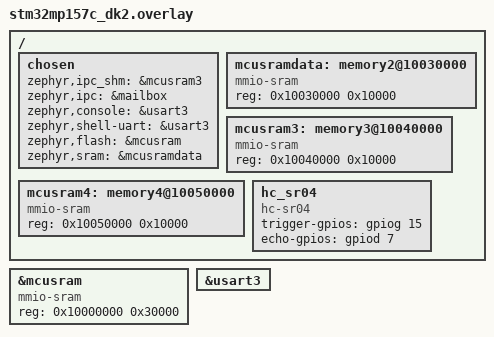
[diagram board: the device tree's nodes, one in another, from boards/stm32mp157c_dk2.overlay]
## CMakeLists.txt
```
cmake_minimum_required(VERSION 3.20.0)

find_package(Zephyr REQUIRED HINTS $ENV{ZEPHYR_BASE})
project(myapp)

# METAL_MAX_DEVICE_REGIONS is used to give the number of memory regions shared
# between processors. By default only one region is defined for the vrings
# and rpmsg buffers. The METAL_MAX_DEVICE_REGIONS has to be redifined to add a
# second region for the resource table.
zephyr_compile_definitions(METAL_MAX_DEVICE_REGIONS=2)

target_include_directories(app PRIVATE ${LIBMETAL_INCLUDE_DIR} ${OPENAMP_INCLUDE_DIR} ${PLATFORM_DIR})

target_sources(app PRIVATE src/main.cpp src/ipc.cpp src/ultrasonic.cpp)
```

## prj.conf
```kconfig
CONFIG_IPM=y
CONFIG_HEAP_MEM_POOL_SIZE=2048
CONFIG_OPENAMP=y
CONFIG_OPENAMP_RSC_TABLE_NUM_RPMSG_BUFF=8
CONFIG_OPENAMP_RSC_TABLE=y
CONFIG_OPENAMP_MASTER=n
CONFIG_SENSOR=y
CONFIG_UART_CONSOLE=y
CONFIG_LOG=y
CONFIG_CPP=y
CONFIG_REQUIRES_FULL_LIBCPP=y
CONFIG_CBPRINTF_FP_SUPPORT=y
CONFIG_ROMSTART_RELOCATION_ROM=y
```

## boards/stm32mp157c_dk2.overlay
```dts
/*
 * Copyright (c) 2020, STMICROLECTRONICS
 *
 * SPDX-License-Identifier: Apache-2.0
 */

/ {
	chosen {
		/*
		 * shared memory reserved for the inter-processor communication
		 */
		zephyr,ipc_shm = &mcusram3;
		zephyr,ipc = &mailbox;
		zephyr,console = &usart3;
		zephyr,shell-uart = &usart3;
		zephyr,flash = &mcusram;
		zephyr,sram = &mcusramdata;
	};

	mcusramdata: memory2@10030000 {
		device_type = "memory";
		compatible = "mmio-sram";
		reg = <0x10030000 0x10000>;
	};

	mcusram3: memory3@10040000 {
		device_type = "memory";
		compatible = "mmio-sram";
		reg = <0x10040000 0x10000>;
	};

	mcusram4: memory4@10050000 {
		device_type = "memory";
		compatible = "mmio-sram";
		reg = <0x10050000 0x10000>;
	};

	hc_sr04: hc_sr04 {
		compatible = "hc-sr04";
		trigger-gpios = <&gpiog 15 GPIO_ACTIVE_HIGH>;
		echo-gpios = <&gpiod 7 GPIO_ACTIVE_HIGH>;
	};
};

&mcusram {
	device_type = "memory";
	compatible = "mmio-sram";
	reg = <0x10000000 0x30000>;
};

&usart3 {
	status = "okay";
};
```

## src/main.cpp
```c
#include <stdio.h>
#include <zephyr/kernel.h>
#include "ipc.hpp"
#include "ultrasonic.hpp"

#define APP_TTY_TASK_STACK_SIZE (1536)
#define APP_ULTRASONIC_TASK_STACK_SIZE (500)
static struct k_thread thread_tty_data;
static struct k_thread thread_ultrasonic_data;
K_THREAD_STACK_DEFINE(thread_tty_stack, APP_TTY_TASK_STACK_SIZE);
K_THREAD_STACK_DEFINE(thread_ultrasonic_stack, APP_TTY_TASK_STACK_SIZE);

int main(void)
{
	k_thread_create(&thread_ultrasonic_data, thread_ultrasonic_stack, APP_ULTRASONIC_TASK_STACK_SIZE, ultrasonic_task, NULL, NULL, NULL, K_PRIO_COOP(7), 0, K_NO_WAIT);
	k_thread_create(&thread_tty_data, thread_tty_stack, APP_TTY_TASK_STACK_SIZE, ipc_task, NULL, NULL, NULL, K_PRIO_COOP(7), 0, K_NO_WAIT);

	while (1)
	{
		// printf("Distance: %.01f cm\n", get_distance());
		k_sleep(K_MSEC(100));
	}
	
	return 0;
}
```

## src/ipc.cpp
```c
#include "ipc.hpp"

#include <zephyr/device.h>
#include <string.h>
#include <stdlib.h>

#include <zephyr/drivers/ipm.h>

#include <openamp/open_amp.h>
#include <metal/device.h>
#include <resource_table.h>

#include "ultrasonic.hpp"

#define RPMSG_CHAN_NAME "rpmsg-tty"
#define SHM_DEVICE_NAME "shm"
// #define CONFIG_OPENAMP_IPC_DEV_NAME "$(dt_chosen_label,$(DT_CHOSEN_Z_IPC))"

#if !DT_HAS_CHOSEN(zephyr_ipc_shm)
#error "Application requires definition of shared memory for rpmsg"
#endif

/* Constants derived from device tree */
#define SHM_NODE        DT_CHOSEN(zephyr_ipc_shm)
#define SHM_START_ADDR  DT_REG_ADDR(SHM_NODE)
#define SHM_SIZE        DT_REG_SIZE(SHM_NODE)

static const struct device *ipm_handle;

static metal_phys_addr_t shm_physmap = SHM_START_ADDR;

struct metal_device shm_device = {
    .name = SHM_DEVICE_NAME,
    .num_regions = 2,
    .regions = {
        {.virt = NULL}, /* shared memory */
        {.virt = NULL}, /* rsc_table memory */
    },
    .node = { NULL },
    .irq_num = 0,
    .irq_info = NULL
};

static struct metal_io_region *shm_io;
static struct rpmsg_virtio_shm_pool shpool;

static struct metal_io_region *rsc_io;
static struct rpmsg_virtio_device rvdev;

static fw_resource_table *rsc_table;

static char rcv_msg[20];
static char tx_buffer[64];
static unsigned int rcv_len;
static struct rpmsg_endpoint rcv_ept;

static K_SEM_DEFINE(data_sem, 0, 1);
static K_SEM_DEFINE(data_rx_sem, 0, 1);

static void platform_ipm_callback(const struct device *device, void *context, uint32_t id, volatile void *data)
{
    k_sem_give(&data_sem);
}

static int rpmsg_recv_callback(struct rpmsg_endpoint *ept, void *data, size_t len, uint32_t src, void *priv)
{
    memcpy(rcv_msg, data, len);
    rcv_len = len;
    k_sem_give(&data_rx_sem);

    return RPMSG_SUCCESS;
}

static void receive_message(char **msg, unsigned int *len)
{
    while (k_sem_take(&data_rx_sem, K_NO_WAIT) != 0) {
        int status = k_sem_take(&data_sem, K_FOREVER);

        if (status == 0)
            rproc_virtio_notified(rvdev.vdev, VRING1_ID);
    }
    *len = rcv_len;
    *msg = rcv_msg;
}

static void new_service_cb(struct rpmsg_device *rdev, const char *name,
                           uint32_t src)
{
    printk("%s: unexpected ns service receive for name %s\n", __func__, name);
}

int mailbox_notify(void *priv, uint32_t id)
{
    ARG_UNUSED(priv);

    ipm_send(ipm_handle, 0, id, NULL, 0);

    return 0;
}

int platform_init(void)
{
    static struct fw_resource_table *rsc_tab_addr;
    int rsc_size;
    struct metal_device *device;
    struct metal_init_params metal_params = METAL_INIT_DEFAULTS;
    int status;

    status = metal_init(&metal_params);
    if (status) {
        printk("metal_init: failed: %d\n", status);
        return -1;
    }

    status = metal_register_generic_device(&shm_device);
    if (status) {
        printk("Couldn't register shared memory: %d\n", status);
        return -1;
    }

    status = metal_device_open("generic", SHM_DEVICE_NAME, &device);
    if (status) {
        printk("metal_device_open failed: %d\n", status);
        return -1;
    }

    /* declare shared memory region */
    metal_io_init(&device->regions[0], (void *)SHM_START_ADDR, &shm_physmap,
                  SHM_SIZE, -1, 0, NULL);

    shm_io = metal_device_io_region(device, 0);
    if (!shm_io) {
        printk("Failed to get shm_io region\n");
        return -1;
    }

    /* declare resource table region */
    rsc_table_get((void**)(&rsc_tab_addr), &rsc_size);
    rsc_table = (fw_resource_table*)rsc_tab_addr;

    metal_io_init(&device->regions[1], rsc_table,
                  (metal_phys_addr_t *)rsc_table, rsc_size, -1, 0, NULL);

    rsc_io = metal_device_io_region(device, 1);
    if (!rsc_io) {
        printk("Failed to get rsc_io region\n");
        return -1;
    }

    /* setup IPM */
    ipm_handle = device_get_binding(CONFIG_OPENAMP_IPC_DEV_NAME);
    if (!ipm_handle) {
        printk("Failed to find ipm device\n");
        return -1;
    }

    ipm_register_callback(ipm_handle, platform_ipm_callback, NULL);

    status = ipm_set_enabled(ipm_handle, 1);
    if (status) {
        printk("ipm_set_enabled failed\n");
        return -1;
    }

    return 0;
}

struct  rpmsg_device *
platform_create_rpmsg_vdev(unsigned int vdev_index,
                           unsigned int role,
                           void (*rst_cb)(struct virtio_device *vdev),
                           rpmsg_ns_bind_cb ns_cb)
{
    struct fw_rsc_vdev_vring *vring_rsc;
    struct virtio_device *vdev;
    int ret;

    vdev = rproc_virtio_create_vdev(VIRTIO_DEV_DEVICE, VDEV_ID,
                                    rsc_table_to_vdev(rsc_table),
                                    rsc_io, NULL, mailbox_notify, NULL);
    if (!vdev) {
        printk("failed to create vdev\r\n");
        return NULL;
    }

    /* wait master rpmsg init completion */
    rproc_virtio_wait_remote_ready(vdev);

    vring_rsc = rsc_table_get_vring0(rsc_table);
    ret = rproc_virtio_init_vring(vdev, 0, vring_rsc->notifyid,
                                  (void *)vring_rsc->da, rsc_io,
                                  vring_rsc->num, vring_rsc->align);
    if (ret) {
        printk("failed to init vring 0\r\n");
        goto failed;
    }

    vring_rsc = rsc_table_get_vring1(rsc_table);
    ret = rproc_virtio_init_vring(vdev, 1, vring_rsc->notifyid,
                                  (void *)vring_rsc->da, rsc_io,
                                  vring_rsc->num, vring_rsc->align);
    if (ret) {
        printk("failed to init vring 1\r\n");
        goto failed;
    }

    rpmsg_virtio_init_shm_pool(&shpool, NULL, SHM_SIZE);
    ret =  rpmsg_init_vdev(&rvdev, vdev, ns_cb, shm_io, &shpool);

    if (ret) {
        printk("failed rpmsg_init_vdev\r\n");
        goto failed;
    }

    return rpmsg_virtio_get_rpmsg_device(&rvdev);

failed:
    rproc_virtio_remove_vdev(vdev);

    return NULL;
}


void ipc_task(void *arg1, void *arg2, void *arg3)
{
    ARG_UNUSED(arg1);
    ARG_UNUSED(arg2);
    ARG_UNUSED(arg3);

    struct rpmsg_device *rpdev;
    char *msg;
    unsigned int len;
    int ret = 0;

    /* Initialize platform */
    ret = platform_init();
    if (ret) {
        printk("Failed to initialize platform\n");
        return;
    }

    rpdev = platform_create_rpmsg_vdev(0, VIRTIO_DEV_DEVICE, NULL,
                                       new_service_cb);
    if (!rpdev) {
        printk("Failed to create rpmsg virtio device\n");
        return;
    }

    ret = rpmsg_create_ept(&rcv_ept, rpdev, RPMSG_CHAN_NAME,
                           RPMSG_ADDR_ANY, RPMSG_ADDR_ANY,
                           rpmsg_recv_callback, NULL);
    if (ret != 0)
        printk("error while creating endpoint(%d)\n", ret);

    /* Handle incoming messsages and send replies when needed */
    for (;;) {
        receive_message(&msg, &len);
        
        int ret = 0;

        if (strcmp(msg, "dist\n") == 0)
        {
            float distance = get_distance();
            ret = snprintf(tx_buffer, sizeof(tx_buffer), "%f", (double)distance);
        }
        else
        {
            ret = snprintf(tx_buffer, sizeof(tx_buffer), "Not known command");
        }

        if (ret > 0)
        {
            rpmsg_send(&rcv_ept, tx_buffer, ret);
        }
        // printk("MESSAGE: %s\n", msg);
    }
}
```

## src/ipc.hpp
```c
#pragma once

void ipc_task(void *, void *, void *);
```

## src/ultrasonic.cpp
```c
#include "ultrasonic.hpp"
#include <zephyr/logging/log.h>
#include <zephyr/drivers/sensor.h>
LOG_MODULE_REGISTER(ultrasonic);

static const struct device *ultrasonic = DEVICE_DT_GET_ONE(hc_sr04);
constexpr int messure_count = 10;
static float distance[messure_count];
static struct k_mutex mutex;

static int trigger_measurement(float &range)
{
	int ret;
	static struct sensor_value distance = {-1, 0};
	
	ret = sensor_sample_fetch(ultrasonic);

	if (0 == ret)
	{
		ret = sensor_channel_get(ultrasonic, SENSOR_CHAN_DISTANCE, &distance);
		
		if (0 == ret)
		{
			k_mutex_lock(&mutex, K_FOREVER);
			range = sensor_value_to_float(&distance);
			k_mutex_unlock(&mutex);
		}
		else
		{
			LOG_ERR("%s - Cannot take measurement: %d", ultrasonic->name, ret);
		}
	}
	else
	{
		LOG_ERR("%s - Cannot take measurement: %d", ultrasonic->name, ret);
	}

	return ret;
}

float get_distance()
{
	float result = 0.f;

	k_mutex_lock(&mutex, K_FOREVER);
	for (auto &&val : distance)
	{
		result += val;
	}
	k_mutex_unlock(&mutex);
	
	return result / messure_count *100.f;
}

static void run(void)
{
	static int idx = 0;

	if (0 == trigger_measurement(distance[idx]))
	{
		idx++;
	}

	if (messure_count == idx)
	{
		idx = 0;
	}
}

void ultrasonic_task(void *arg1, void *arg2, void *arg3)
{
	if (!device_is_ready(ultrasonic)) {
		LOG_ERR("Device %s is not ready\n", ultrasonic->name);
		return;
	}

	k_mutex_init(&mutex);

	while (1)
	{
		run();
		k_sleep(K_MSEC(20));
	}
}
```

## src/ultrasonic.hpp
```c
#pragma once

void ultrasonic_task(void *, void *, void *);
float get_distance();
```
